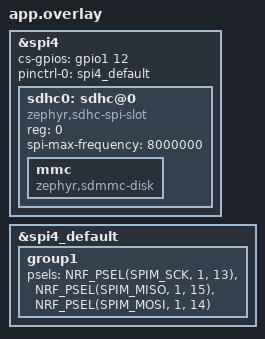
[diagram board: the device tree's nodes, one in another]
&spi4 {
	status = "okay";
	cs-gpios = <&gpio1 12 GPIO_ACTIVE_HIGH>;
	pinctrl-0 = <&spi4_default>;
	sdhc0: sdhc@0 {
			compatible = "zephyr,sdhc-spi-slot";
			reg = <0>;
			status = "okay";
			mmc {
				compatible = "zephyr,sdmmc-disk";
				status = "okay";
			};
			spi-max-frequency = <8000000>;
	};
};

&spi4_default {
	group1 {
		psels = <NRF_PSEL(SPIM_SCK, 1, 13)>,
				<NRF_PSEL(SPIM_MISO, 1, 15)>,
				<NRF_PSEL(SPIM_MOSI, 1, 14)>;
	};
};

